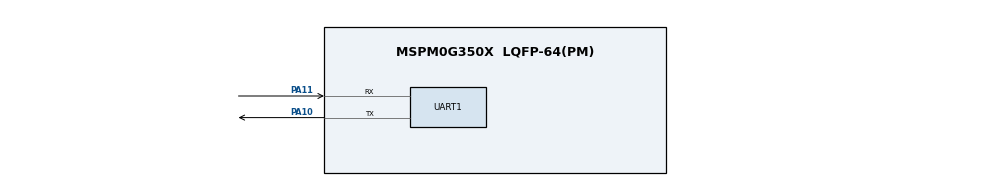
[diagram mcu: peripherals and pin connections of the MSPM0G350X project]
/**
 * @cliArgs --device "MSPM0G350X" --part "Default" --package "LQFP-64(PM)" --product "mspm0_sdk@2.02.00.05"
 * @versions {"tool":"1.21.0+3721"}
 */

/**
 * Import the modules used in this configuration.
 */
const GPIO   = scripting.addModule("/ti/driverlib/GPIO", {}, false);
const GPIO1  = GPIO.addInstance();
const SYSCTL = scripting.addModule("/ti/driverlib/SYSCTL");
const UART   = scripting.addModule("/ti/driverlib/UART", {}, false);
const UART1  = UART.addInstance();

/**
 * Write custom configuration values to the imported modules.
 */
GPIO1.$name                          = "GPIO";
GPIO1.associatedPins[0].$name        = "BTN_1";
GPIO1.associatedPins[0].direction    = "INPUT";
GPIO1.associatedPins[0].assignedPort = "PORTA";
GPIO1.associatedPins[0].assignedPin  = "18";
GPIO1.associatedPins[0].interruptEn  = true;
GPIO1.associatedPins[0].polarity     = "RISE";

const Board = scripting.addModule("/ti/driverlib/Board", {}, false);

SYSCTL.forceDefaultClkConfig = true;

UART1.$name                            = "UART";
UART1.uartClkSrc                       = "LFCLK";
UART1.ovsRate                          = "3";
UART1.enableFIFO                       = true;
UART1.rxFifoThreshold                  = "DL_UART_RX_FIFO_LEVEL_ONE_ENTRY";
UART1.enableDMARX                      = false;
UART1.enableDMATX                      = false;
UART1.enabledInterrupts                = ["BREAK_ERROR","FRAMING_ERROR","NOISE_ERROR","OVERRUN_ERROR","PARITY_ERROR","RX"];
UART1.peripheral.rxPin.$assign         = "PA11";
UART1.peripheral.txPin.$assign         = "PA10";
UART1.txPinConfig.$name                = "ti_driverlib_gpio_GPIOPinGeneric0";
UART1.txPinConfig.direction            = scripting.forceWrite("OUTPUT");
UART1.txPinConfig.hideOutputInversion  = scripting.forceWrite(false);
UART1.txPinConfig.onlyInternalResistor = scripting.forceWrite(false);
UART1.txPinConfig.passedPeripheralType = scripting.forceWrite("Digital");
UART1.rxPinConfig.$name                = "ti_driverlib_gpio_GPIOPinGeneric1";
UART1.rxPinConfig.hideOutputInversion  = scripting.forceWrite(false);
UART1.rxPinConfig.onlyInternalResistor = scripting.forceWrite(false);
UART1.rxPinConfig.passedPeripheralType = scripting.forceWrite("Digital");

/**
 * Pinmux solution for unlocked pins/peripherals. This ensures that minor changes to the automatic solver in a future
 * version of the tool will not impact the pinmux you originally saw.  These lines can be completely deleted in order to
 * re-solve from scratch.
 */
GPIO1.associatedPins[0].pin.$suggestSolution = "PA18";
Board.peripheral.$suggestSolution            = "DEBUGSS";
Board.peripheral.swclkPin.$suggestSolution   = "PA20";
Board.peripheral.swdioPin.$suggestSolution   = "PA19";
SYSCTL.peripheral.$suggestSolution           = "SYSCTL";
UART1.peripheral.$suggestSolution            = "UART0";
